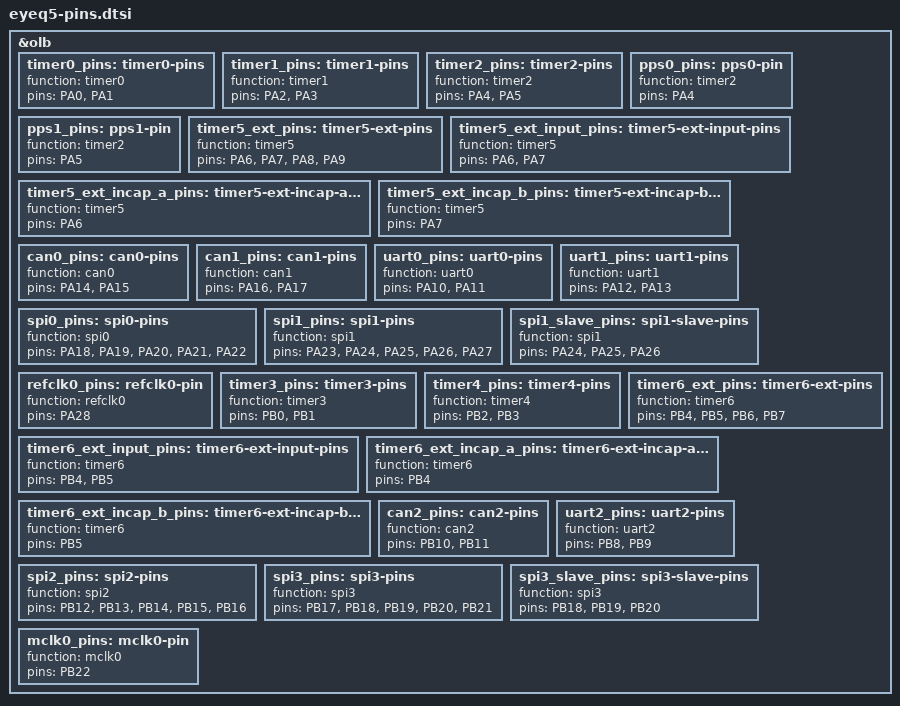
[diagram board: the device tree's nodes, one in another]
// SPDX-License-Identifier: (GPL-2.0-only OR BSD-2-Clause)

/*
 * Default pin configuration for Mobileye EyeQ5 boards. We mostly create one
 * pin configuration node per function.
 */

&olb {
	timer0_pins: timer0-pins {
		function = "timer0";
		pins = "PA0", "PA1";
	};
	timer1_pins: timer1-pins {
		function = "timer1";
		pins = "PA2", "PA3";
	};
	timer2_pins: timer2-pins {
		function = "timer2";
		pins = "PA4", "PA5";
	};
	pps0_pins: pps0-pin {
		function = "timer2";
		pins = "PA4";
	};
	pps1_pins: pps1-pin {
		function = "timer2";
		pins = "PA5";
	};
	timer5_ext_pins: timer5-ext-pins {
		function = "timer5";
		pins = "PA6", "PA7", "PA8", "PA9";
	};
	timer5_ext_input_pins: timer5-ext-input-pins {
		function = "timer5";
		pins = "PA6", "PA7";
	};
	timer5_ext_incap_a_pins: timer5-ext-incap-a-pin {
		function = "timer5";
		pins = "PA6";
	};
	timer5_ext_incap_b_pins: timer5-ext-incap-b-pin {
		function = "timer5";
		pins = "PA7";
	};
	can0_pins: can0-pins {
		function = "can0";
		pins = "PA14", "PA15";
	};
	can1_pins: can1-pins {
		function = "can1";
		pins = "PA16", "PA17";
	};
	uart0_pins: uart0-pins {
		function = "uart0";
		pins = "PA10", "PA11";
	};
	uart1_pins: uart1-pins {
		function = "uart1";
		pins = "PA12", "PA13";
	};
	spi0_pins: spi0-pins {
		function = "spi0";
		pins = "PA18", "PA19", "PA20", "PA21", "PA22";
	};
	spi1_pins: spi1-pins {
		function = "spi1";
		pins = "PA23", "PA24", "PA25", "PA26", "PA27";
	};
	spi1_slave_pins: spi1-slave-pins {
		function = "spi1";
		pins = "PA24", "PA25", "PA26";
	};
	refclk0_pins: refclk0-pin {
		function = "refclk0";
		pins = "PA28";
	};
	timer3_pins: timer3-pins {
		function = "timer3";
		pins = "PB0", "PB1";
	};
	timer4_pins: timer4-pins {
		function = "timer4";
		pins = "PB2", "PB3";
	};
	timer6_ext_pins: timer6-ext-pins {
		function = "timer6";
		pins = "PB4", "PB5", "PB6", "PB7";
	};
	timer6_ext_input_pins: timer6-ext-input-pins {
		function = "timer6";
		pins = "PB4", "PB5";
	};
	timer6_ext_incap_a_pins: timer6-ext-incap-a-pin {
		function = "timer6";
		pins = "PB4";
	};
	timer6_ext_incap_b_pins: timer6-ext-incap-b-pin {
		function = "timer6";
		pins = "PB5";
	};
	can2_pins: can2-pins {
		function = "can2";
		pins = "PB10", "PB11";
	};
	uart2_pins: uart2-pins {
		function = "uart2";
		pins = "PB8", "PB9";
	};
	spi2_pins: spi2-pins {
		function = "spi2";
		pins = "PB12", "PB13", "PB14", "PB15", "PB16";
	};
	spi3_pins: spi3-pins {
		function = "spi3";
		pins = "PB17", "PB18", "PB19", "PB20", "PB21";
	};
	spi3_slave_pins: spi3-slave-pins {
		function = "spi3";
		pins = "PB18", "PB19", "PB20";
	};
	mclk0_pins: mclk0-pin {
		function = "mclk0";
		pins = "PB22";
	};
};
